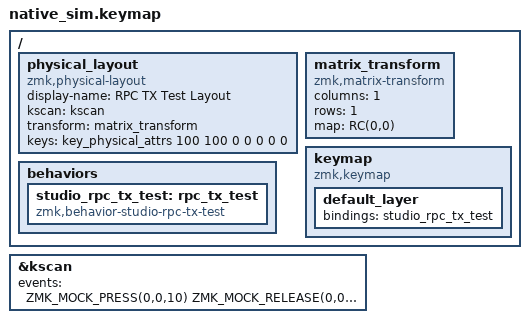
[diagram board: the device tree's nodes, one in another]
#include <behaviors.dtsi>
#include <dt-bindings/zmk/kscan_mock.h>
#include <dt-bindings/zmk/matrix_transform.h>
#include <physical_layouts.dtsi>

/ {
    physical_layout: physical_layout {
        compatible = "zmk,physical-layout";
        display-name = "RPC TX Test Layout";
        kscan = <&kscan>;
        transform = <&matrix_transform>;
        keys = <&key_physical_attrs 100 100 0 0 0 0 0>;
    };

    matrix_transform: matrix_transform {
        compatible = "zmk,matrix-transform";
        columns = <1>;
        rows = <1>;
        map = <RC(0,0)>;
    };

    behaviors {
        studio_rpc_tx_test: rpc_tx_test {
            compatible = "zmk,behavior-studio-rpc-tx-test";
            #binding-cells = <0>;
        };
    };

    keymap {
        compatible = "zmk,keymap";

        default_layer {
            bindings = <&studio_rpc_tx_test>;
        };
    };
};

&kscan {
    events = <
        ZMK_MOCK_PRESS(0,0,10)
        /* Allow the asynchronous test transport to drain and validate the response. */
        ZMK_MOCK_RELEASE(0,0,500)
    >;
};
